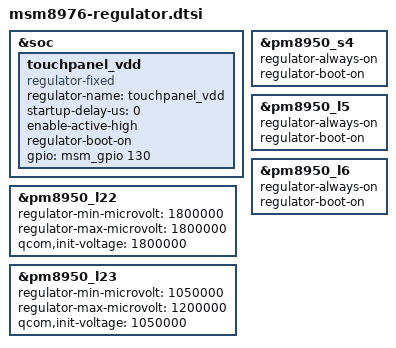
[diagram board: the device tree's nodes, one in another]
/*
 * Copyright (c) 2014-2016, The Linux Foundation. All rights reserved.
 *
 * This program is free software; you can redistribute it and/or modify
 * it under the terms of the GNU General Public License version 2 and
 * only version 2 as published by the Free Software Foundation.
 *
 * This program is distributed in the hope that it will be useful,
 * but WITHOUT ANY WARRANTY; without even the implied warranty of
 * MERCHANTABILITY or FITNESS FOR A PARTICULAR PURPOSE.  See the
 * GNU General Public License for more details.
 */

&soc {
    touchpanel_vdd: touchpanel_vdd {
        compatible = "regulator-fixed";
        regulator-name = "touchpanel_vdd";
        startup-delay-us = <0>;
        enable-active-high;
        regulator-boot-on;
        gpio = <&msm_gpio 130 0>;
    };

    /delete-node/ adv_vreg;
};

&pm8950_s4 {
    regulator-always-on;
    regulator-boot-on;
};

&pm8950_l5 {
    regulator-always-on;
    regulator-boot-on;
};

&pm8950_l6 {
    regulator-always-on;
    regulator-boot-on;
};

&pm8950_l22 {
    regulator-min-microvolt = <1800000>;
    regulator-max-microvolt = <1800000>;
    qcom,init-voltage = <1800000>;
};

&pm8950_l23 {
    regulator-min-microvolt = <1050000>;
    regulator-max-microvolt = <1200000>;
    qcom,init-voltage = <1050000>;
};
